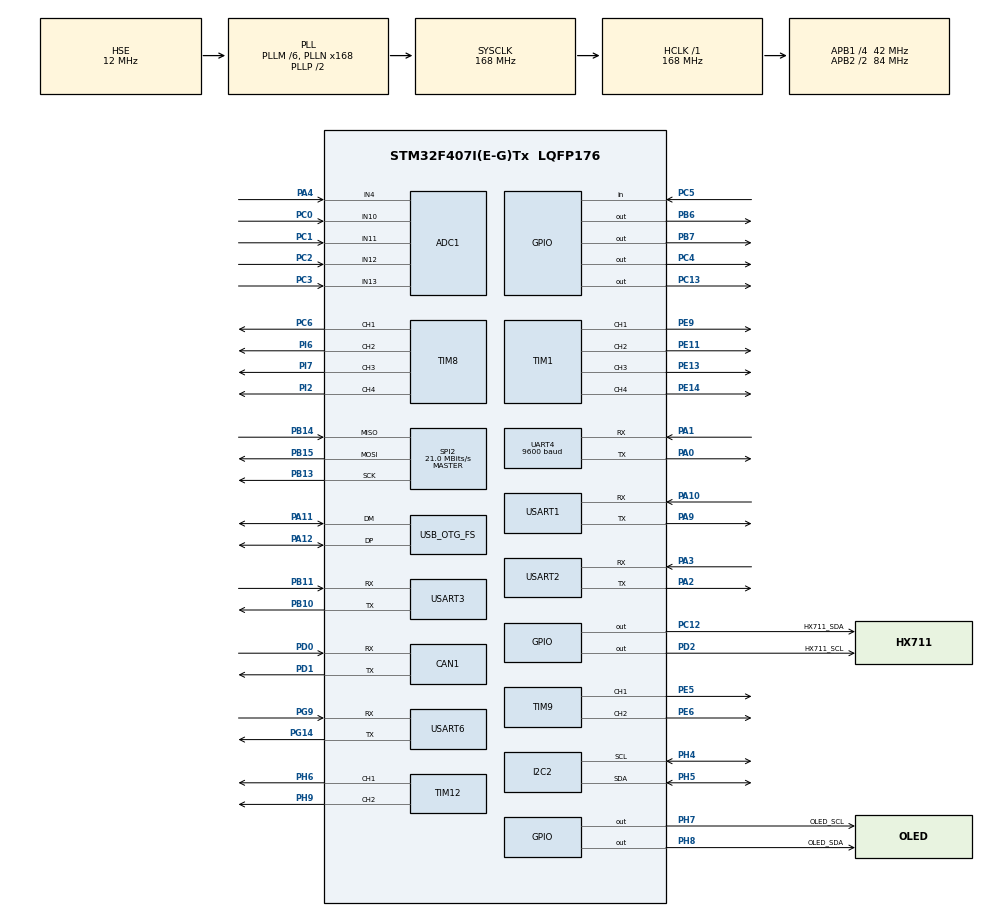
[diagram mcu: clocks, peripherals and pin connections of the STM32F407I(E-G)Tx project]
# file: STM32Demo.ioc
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ADC1.Channel-0\#ChannelRegularConversion=ADC_CHANNEL_4
ADC1.Channel-1\#ChannelRegularConversion=ADC_CHANNEL_10
ADC1.Channel-2\#ChannelRegularConversion=ADC_CHANNEL_11
ADC1.Channel-3\#ChannelRegularConversion=ADC_CHANNEL_12
ADC1.Channel-4\#ChannelRegularConversion=ADC_CHANNEL_13
ADC1.DiscontinuousConvMode=ENABLE
ADC1.NbrOfConversion=5
ADC1.NbrOfConversionFlag=1
ADC1.Rank-0\#ChannelRegularConversion=1
ADC1.Rank-1\#ChannelRegularConversion=2
ADC1.Rank-2\#ChannelRegularConversion=3
ADC1.Rank-3\#ChannelRegularConversion=4
ADC1.Rank-4\#ChannelRegularConversion=5
ADC1.SamplingTime-0\#ChannelRegularConversion=ADC_SAMPLETIME_3CYCLES
ADC1.SamplingTime-1\#ChannelRegularConversion=ADC_SAMPLETIME_3CYCLES
ADC1.SamplingTime-2\#ChannelRegularConversion=ADC_SAMPLETIME_3CYCLES
ADC1.SamplingTime-3\#ChannelRegularConversion=ADC_SAMPLETIME_3CYCLES
ADC1.SamplingTime-4\#ChannelRegularConversion=ADC_SAMPLETIME_3CYCLES
ADC1.ScanConvMode=ENABLE
ADC1.master=1
CAN1.BS1=CAN_BS1_1TQ
CAN1.BS2=CAN_BS2_1TQ
CAN1.CalculateTimeQuantum=380.95238095238096
Dma.Request0=USART1_TX
Dma.Request1=USART3_TX
Dma.Request2=USART2_TX
Dma.USART1_TX.0.Direction=DMA_MEMORY_TO_PERIPH
Dma.USART1_TX.0.FIFOMode=DMA_FIFOMODE_DISABLE
Dma.USART1_TX.0.Instance=DMA2_Stream7
Dma.USART1_TX.0.MemDataAlignment=DMA_MDATAALIGN_BYTE
Dma.USART1_TX.0.MemInc=DMA_MINC_ENABLE
Dma.USART1_TX.0.Mode=DMA_NORMAL
Dma.USART1_TX.0.PeriphDataAlignment=DMA_PDATAALIGN_BYTE
Dma.USART1_TX.0.PeriphInc=DMA_PINC_DISABLE
Dma.USART1_TX.0.Priority=DMA_PRIORITY_LOW
Dma.USART2_TX.2.Direction=DMA_MEMORY_TO_PERIPH
Dma.USART2_TX.2.FIFOMode=DMA_FIFOMODE_DISABLE
Dma.USART2_TX.2.Instance=DMA1_Stream6
Dma.USART2_TX.2.MemDataAlignment=DMA_MDATAALIGN_BYTE
Dma.USART2_TX.2.MemInc=DMA_MINC_ENABLE
Dma.USART2_TX.2.Mode=DMA_NORMAL
Dma.USART2_TX.2.PeriphDataAlignment=DMA_PDATAALIGN_BYTE
Dma.USART2_TX.2.PeriphInc=DMA_PINC_DISABLE
Dma.USART2_TX.2.Priority=DMA_PRIORITY_LOW
Dma.USART3_TX.1.Direction=DMA_MEMORY_TO_PERIPH
Dma.USART3_TX.1.FIFOMode=DMA_FIFOMODE_DISABLE
Dma.USART3_TX.1.Instance=DMA1_Stream3
Dma.USART3_TX.1.MemDataAlignment=DMA_MDATAALIGN_BYTE
Dma.USART3_TX.1.MemInc=DMA_MINC_ENABLE
Dma.USART3_TX.1.Mode=DMA_NORMAL
Dma.USART3_TX.1.PeriphDataAlignment=DMA_PDATAALIGN_BYTE
Dma.USART3_TX.1.PeriphInc=DMA_PINC_DISABLE
Dma.USART3_TX.1.Priority=DMA_PRIORITY_LOW
FREERTOS.Tasks01=Task01,24,128,StartDefaultTask,Default,NULL,Dynamic,NULL,NULL;Task02,24,128,StartTask02,Default,NULL,Dynamic,NULL,NULL;Task03,24,128,StartTask03,Default,NULL,Dynamic,NULL,NULL;Task04,24,128,StartTask04,Default,NULL,Dynamic,NULL,NULL;Task05,24,128,StartTask05,Default,NULL,Dynamic,NULL,NULL;Task06,24,128,StartTask06,Default,NULL,Dynamic,NULL,NULL
FREERTOS.configENABLE_FPU=1
Mcu.Family=STM32F4
Mcu.Name=STM32F407I(E-G)Tx
Mcu.Package=LQFP176
NVIC.DMA1_Stream3_IRQn=true\:5\:0\:false\:false\:true\:true\:false\:true
NVIC.DMA1_Stream6_IRQn=true\:5\:0\:false\:false\:true\:true\:false\:true
NVIC.DMA2_Stream7_IRQn=true\:5\:0\:false\:false\:true\:true\:false\:true
NVIC.OTG_FS_IRQn=true\:5\:0\:false\:false\:true\:false\:false\:true
NVIC.PriorityGroup=NVIC_PRIORITYGROUP_4
NVIC.TIM7_IRQn=true\:0\:0\:false\:false\:true\:false\:false\:true
NVIC.TimeBase=TIM7_IRQn
NVIC.TimeBaseIP=TIM7
NVIC.UART4_IRQn=true\:5\:0\:false\:false\:true\:false\:true\:true
NVIC.USART1_IRQn=true\:5\:0\:false\:false\:true\:false\:true\:true
NVIC.USART2_IRQn=true\:5\:0\:false\:false\:true\:false\:true\:true
NVIC.USART3_IRQn=true\:5\:0\:false\:false\:true\:false\:true\:true
NVIC.USART6_IRQn=true\:5\:0\:false\:false\:true\:false\:true\:true
PA0-WKUP.Mode=Asynchronous
PA0-WKUP.Signal=UART4_TX
PA1.Mode=Asynchronous
PA1.Signal=UART4_RX
PA10.Mode=Asynchronous
PA10.Signal=USART1_RX
PA11.Mode=Device_Only
PA11.Signal=USB_OTG_FS_DM
PA12.Mode=Device_Only
PA12.Signal=USB_OTG_FS_DP
PA13.Mode=Serial_Wire
PA13.Signal=SYS_JTMS-SWDIO
PA14.Mode=Serial_Wire
PA14.Signal=SYS_JTCK-SWCLK
PA2.Mode=Asynchronous
PA2.Signal=USART2_TX
PA3.Mode=Asynchronous
PA3.Signal=USART2_RX
PA4.Signal=ADCx_IN4
PA9.Mode=Asynchronous
PA9.Signal=USART1_TX
PB10.Mode=Asynchronous
PB10.Signal=USART3_TX
PB11.Mode=Asynchronous
PB11.Signal=USART3_RX
PB13.Mode=Full_Duplex_Master
PB13.Signal=SPI2_SCK
PB14.Mode=Full_Duplex_Master
PB14.Signal=SPI2_MISO
PB15.Mode=Full_Duplex_Master
PB15.Signal=SPI2_MOSI
PB6.GPIO_ModeDefaultOutputPP=GPIO_MODE_OUTPUT_OD
PB6.GPIO_PuPd=GPIO_PULLUP
PB6.GPIO_Speed=GPIO_SPEED_FREQ_VERY_HIGH
PB6.Signal=GPIO_Output
PB7.GPIO_ModeDefaultOutputPP=GPIO_MODE_OUTPUT_OD
PB7.GPIO_PuPd=GPIO_PULLUP
PB7.GPIO_Speed=GPIO_SPEED_FREQ_VERY_HIGH
PB7.Signal=GPIO_Output
PC0.Signal=ADCx_IN10
PC1.Signal=ADCx_IN11
PC10.Signal=SDIO_D2
PC11.Signal=SDIO_D3
PC12.GPIO_Label=HX711_SDA
PC12.GPIO_ModeDefaultOutputPP=GPIO_MODE_OUTPUT_OD
PC12.GPIO_PuPd=GPIO_PULLUP
PC12.GPIO_Speed=GPIO_SPEED_FREQ_VERY_HIGH
PC12.PinState=GPIO_PIN_SET
PC12.Signal=GPIO_Output
PC13-ANTI_TAMP.GPIO_Speed=GPIO_SPEED_FREQ_LOW
PC13-ANTI_TAMP.Signal=GPIO_Output
PC14-OSC32_IN.Mode=LSE-External-Oscillator
PC14-OSC32_IN.Signal=RCC_OSC32_IN
PC15-OSC32_OUT.Mode=LSE-External-Oscillator
PC15-OSC32_OUT.Signal=RCC_OSC32_OUT
PC2.Signal=ADCx_IN12
PC3.Signal=ADCx_IN13
PC4.GPIO_ModeDefaultOutputPP=GPIO_MODE_OUTPUT_OD
PC4.GPIO_PuPd=GPIO_PULLUP
PC4.GPIO_Speed=GPIO_SPEED_FREQ_VERY_HIGH
PC4.PinState=GPIO_PIN_SET
PC4.Signal=GPIO_Output
PC5.Signal=GPIO_Input
PC6.GPIO_Speed=GPIO_SPEED_FREQ_VERY_HIGH
PC6.Signal=S_TIM8_CH1
PC8.Signal=SDIO_D0
PC9.Signal=SDIO_D1
PD0.Mode=Master
PD0.Signal=CAN1_RX
PD1.Mode=Master
PD1.Signal=CAN1_TX
PD2.GPIO_Label=HX711_SCL
PD2.GPIO_ModeDefaultOutputPP=GPIO_MODE_OUTPUT_PP
PD2.GPIO_PuPd=GPIO_PULLUP
PD2.GPIO_Speed=GPIO_SPEED_FREQ_VERY_HIGH
PD2.PinState=GPIO_PIN_SET
PD2.Signal=GPIO_Output
PE11.GPIO_Speed=GPIO_SPEED_FREQ_VERY_HIGH
PE11.Signal=S_TIM1_CH2
PE13.GPIO_Speed=GPIO_SPEED_FREQ_VERY_HIGH
PE13.Signal=S_TIM1_CH3
PE14.GPIO_Speed=GPIO_SPEED_FREQ_VERY_HIGH
PE14.Signal=S_TIM1_CH4
PE5.GPIO_Speed=GPIO_SPEED_FREQ_VERY_HIGH
PE5.Signal=S_TIM9_CH1
PE6.GPIO_Speed=GPIO_SPEED_FREQ_VERY_HIGH
PE6.Signal=S_TIM9_CH2
PE9.GPIO_Speed=GPIO_SPEED_FREQ_VERY_HIGH
PE9.Signal=S_TIM1_CH1
PG14.Mode=Asynchronous
PG14.Signal=USART6_TX
PG9.Mode=Asynchronous
PG9.Signal=USART6_RX
PH0-OSC_IN.Mode=HSE-External-Oscillator
PH0-OSC_IN.Signal=RCC_OSC_IN
PH1-OSC_OUT.Mode=HSE-External-Oscillator
PH1-OSC_OUT.Signal=RCC_OSC_OUT
PH4.Mode=I2C
PH4.Signal=I2C2_SCL
PH5.Mode=I2C
PH5.Signal=I2C2_SDA
PH6.GPIO_Speed=GPIO_SPEED_FREQ_VERY_HIGH
PH6.Signal=S_TIM12_CH1
PH7.GPIO_Label=OLED_SCL
PH7.GPIO_ModeDefaultOutputPP=GPIO_MODE_OUTPUT_OD
PH7.GPIO_PuPd=GPIO_PULLUP
PH7.GPIO_Speed=GPIO_SPEED_FREQ_VERY_HIGH
PH7.Signal=GPIO_Output
PH8.GPIO_Label=OLED_SDA
PH8.GPIO_ModeDefaultOutputPP=GPIO_MODE_OUTPUT_OD
PH8.GPIO_PuPd=GPIO_PULLUP
PH8.GPIO_Speed=GPIO_SPEED_FREQ_VERY_HIGH
PH8.Signal=GPIO_Output
PH9.GPIO_Speed=GPIO_SPEED_FREQ_VERY_HIGH
PH9.Signal=S_TIM12_CH2
PI2.GPIO_Speed=GPIO_SPEED_FREQ_VERY_HIGH
PI2.Signal=S_TIM8_CH4
PI6.GPIO_Speed=GPIO_SPEED_FREQ_VERY_HIGH
PI6.Signal=S_TIM8_CH2
PI7.GPIO_Speed=GPIO_SPEED_FREQ_VERY_HIGH
PI7.Signal=S_TIM8_CH3
ProjectManager.HeapSize=0x200
ProjectManager.StackSize=0x400
ProjectManager.TargetToolchain=MDK-ARM V5.27
RCC.48MHZClocksFreq_Value=48000000
RCC.AHBFreq_Value=168000000
RCC.APB1CLKDivider=RCC_HCLK_DIV4
RCC.APB1Freq_Value=42000000
RCC.APB1TimFreq_Value=84000000
RCC.APB2CLKDivider=RCC_HCLK_DIV2
RCC.APB2Freq_Value=84000000
RCC.APB2TimFreq_Value=168000000
RCC.CortexFreq_Value=168000000
RCC.HCLKFreq_Value=168000000
RCC.HSE_VALUE=12000000
RCC.HSI_VALUE=16000000
RCC.PLLM=6
RCC.PLLN=168
RCC.PLLQ=7
RCC.SYSCLKFreq_VALUE=168000000
RCC.SYSCLKSource=RCC_SYSCLKSOURCE_PLLCLK
RCC.VCOOutputFreq_Value=336000000
SH.ADCx_IN10.0=ADC1_IN10,IN10
SH.ADCx_IN11.0=ADC1_IN11,IN11
SH.ADCx_IN12.0=ADC1_IN12,IN12
SH.ADCx_IN13.0=ADC1_IN13,IN13
SH.ADCx_IN4.0=ADC1_IN4,IN4
SH.S_TIM12_CH1.0=TIM12_CH1,PWM Generation1 CH1
SH.S_TIM12_CH2.0=TIM12_CH2,PWM Generation2 CH2
SH.S_TIM1_CH1.0=TIM1_CH1,PWM Generation1 CH1
SH.S_TIM1_CH2.0=TIM1_CH2,PWM Generation2 CH2
SH.S_TIM1_CH3.0=TIM1_CH3,PWM Generation3 CH3
SH.S_TIM1_CH4.0=TIM1_CH4,PWM Generation4 CH4
SH.S_TIM8_CH1.0=TIM8_CH1,PWM Generation1 CH1
SH.S_TIM8_CH2.0=TIM8_CH2,PWM Generation2 CH2
SH.S_TIM8_CH3.0=TIM8_CH3,PWM Generation3 CH3
SH.S_TIM8_CH4.0=TIM8_CH4,PWM Generation4 CH4
SH.S_TIM9_CH1.0=TIM9_CH1,PWM Generation1 CH1
SH.S_TIM9_CH2.0=TIM9_CH2,PWM Generation2 CH2
SPI2.BaudRatePrescaler=SPI_BAUDRATEPRESCALER_2
SPI2.CalculateBaudRate=21.0 MBits/s
SPI2.Direction=SPI_DIRECTION_2LINES
SPI2.Mode=SPI_MODE_MASTER
SPI2.VirtualType=VM_MASTER
TIM1.Channel-PWM\ Generation1\ CH1=TIM_CHANNEL_1
TIM1.Channel-PWM\ Generation2\ CH2=TIM_CHANNEL_2
TIM1.Channel-PWM\ Generation3\ CH3=TIM_CHANNEL_3
TIM1.Channel-PWM\ Generation4\ CH4=TIM_CHANNEL_4
TIM12.Channel-PWM\ Generation1\ CH1=TIM_CHANNEL_1
TIM12.Channel-PWM\ Generation2\ CH2=TIM_CHANNEL_2
TIM8.Channel-PWM\ Generation1\ CH1=TIM_CHANNEL_1
TIM8.Channel-PWM\ Generation2\ CH2=TIM_CHANNEL_2
TIM8.Channel-PWM\ Generation3\ CH3=TIM_CHANNEL_3
TIM8.Channel-PWM\ Generation4\ CH4=TIM_CHANNEL_4
TIM9.Channel-PWM\ Generation1\ CH1=TIM_CHANNEL_1
TIM9.Channel-PWM\ Generation2\ CH2=TIM_CHANNEL_2
UART4.BaudRate=9600
UART4.VirtualMode=Asynchronous
USART1.VirtualMode=VM_ASYNC
USART2.VirtualMode=VM_ASYNC
USART3.VirtualMode=VM_ASYNC
USART6.VirtualMode=VM_ASYNC
USB_DEVICE.CLASS_NAME_FS=MSC
USB_DEVICE.VirtualMode-MSC_FS=Msc
USB_DEVICE.VirtualModeFS=Msc_FS
USB_OTG_FS.VirtualMode=Device_Only
VP_FATFS_VS_Generic.Mode=User_defined
VP_FREERTOS_VS_CMSIS_V2.Mode=CMSIS_V2
VP_SYS_VS_tim7.Mode=TIM7
VP_TIM1_VS_ClockSourceINT.Mode=Internal
VP_TIM8_VS_ClockSourceINT.Mode=Internal
VP_TIM9_VS_ClockSourceINT.Mode=Internal
VP_USB_DEVICE_VS_USB_DEVICE_MSC_FS.Mode=MSC_FS
board=custom

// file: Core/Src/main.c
/* USER CODE BEGIN Header */
/**
  ******************************************************************************
  * @file           : main.c
  * @brief          : Main program body
  ******************************************************************************
  * @attention
  *
  * <h2><center>&copy; Copyright (c) 2021 STMicroelectronics.
  * All rights reserved.</center></h2>
  *
  * This software component is licensed by ST under BSD 3-Clause license,
  * the "License"; You may not use this file except in compliance with the
  * License. You may obtain a copy of the License at:
  *                        opensource.org/licenses/BSD-3-Clause
  *
  ******************************************************************************
  */
/* USER CODE END Header */
#include "main.h"
#include "cmsis_os.h"
#include "adc.h"
#include "can.h"
#include "dma.h"
#include "fatfs.h"
#include "i2c.h"
#include "spi.h"
#include "tim.h"
#include "usart.h"
#include "usb_device.h"
#include "gpio.h"

void SystemClock_Config(void);
void MX_FREERTOS_Init(void);

int main(void)
{

  /* MCU Configuration--------------------------------------------------------*/

  /* Reset of all peripherals, Initializes the Flash interface and the Systick. */  HAL_Init();

  /* Configure the system clock */
  SystemClock_Config();

  /* Initialize all configured peripherals */
  MX_GPIO_Init();
  MX_DMA_Init();
  MX_ADC1_Init();
  MX_CAN1_Init();
  MX_I2C2_Init();
  MX_SPI2_Init();
  MX_TIM1_Init();
  MX_TIM8_Init();
  MX_TIM9_Init();
  MX_TIM12_Init();
  MX_UART4_Init();
  MX_USART1_UART_Init();
  MX_USART2_UART_Init();
  MX_USART3_UART_Init();
  MX_USART6_UART_Init();
  MX_FATFS_Init();

  /* Init scheduler */
  osKernelInitialize();  /* Call init function for freertos objects (in freertos.c) */
  MX_FREERTOS_Init();
  /* Start scheduler */
  osKernelStart();

  /* We should never get here as control is now taken by the scheduler */
  /* Infinite loop */
  while (1)
  {

  }
}

void SystemClock_Config(void)
{
  RCC_OscInitTypeDef RCC_OscInitStruct = {0};
  RCC_ClkInitTypeDef RCC_ClkInitStruct = {0};

  /** Configure the main internal regulator output voltage
  */
  __HAL_RCC_PWR_CLK_ENABLE();
  __HAL_PWR_VOLTAGESCALING_CONFIG(PWR_REGULATOR_VOLTAGE_SCALE1);
  /** Initializes the RCC Oscillators according to the specified parameters
  * in the RCC_OscInitTypeDef structure.
  */
  RCC_OscInitStruct.OscillatorType = RCC_OSCILLATORTYPE_HSE;
  RCC_OscInitStruct.HSEState = RCC_HSE_ON;
  RCC_OscInitStruct.PLL.PLLState = RCC_PLL_ON;
  RCC_OscInitStruct.PLL.PLLSource = RCC_PLLSOURCE_HSE;
  RCC_OscInitStruct.PLL.PLLM = 6;
  RCC_OscInitStruct.PLL.PLLN = 168;
  RCC_OscInitStruct.PLL.PLLP = RCC_PLLP_DIV2;
  RCC_OscInitStruct.PLL.PLLQ = 7;
  if (HAL_RCC_OscConfig(&RCC_OscInitStruct) != HAL_OK)
  {
    Error_Handler();
  }
  /** Initializes the CPU, AHB and APB buses clocks
  */
  RCC_ClkInitStruct.ClockType = RCC_CLOCKTYPE_HCLK|RCC_CLOCKTYPE_SYSCLK
                              |RCC_CLOCKTYPE_PCLK1|RCC_CLOCKTYPE_PCLK2;
  RCC_ClkInitStruct.SYSCLKSource = RCC_SYSCLKSOURCE_PLLCLK;
  RCC_ClkInitStruct.AHBCLKDivider = RCC_SYSCLK_DIV1;
  RCC_ClkInitStruct.APB1CLKDivider = RCC_HCLK_DIV4;
  RCC_ClkInitStruct.APB2CLKDivider = RCC_HCLK_DIV2;

  if (HAL_RCC_ClockConfig(&RCC_ClkInitStruct, FLASH_LATENCY_5) != HAL_OK)
  {
    Error_Handler();
  }
}

void HAL_TIM_PeriodElapsedCallback(TIM_HandleTypeDef *htim)
{
  if (htim->Instance == TIM7) {
    HAL_IncTick();
  }
}

void Error_Handler(void)
{
}

/************************ (C) COPYRIGHT STMicroelectronics *****END OF FILE****/

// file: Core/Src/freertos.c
/* USER CODE BEGIN Header */
/**
  ******************************************************************************
  * File Name          : freertos.c
  * Description        : Code for freertos applications
  ******************************************************************************
  * @attention
  *
  * <h2><center>&copy; Copyright (c) 2021 STMicroelectronics.
  * All rights reserved.</center></h2>
  *
  * This software component is licensed by ST under Ultimate Liberty license
  * SLA0044, the "License"; You may not use this file except in compliance with
  * the License. You may obtain a copy of the License at:
  *                             www.st.com/SLA0044
  *
  ******************************************************************************
  */
/* USER CODE END Header */

#include "FreeRTOS.h"
#include "task.h"
#include "main.h"
#include "cmsis_os.h"

/* USER CODE BEGIN Includes */
#include "Task01Main.h"
#include "Task02Main.h"
#include "Task03Main.h"
#include "Task04Main.h"
#include "Task05Main.h"
#include "Task06Main.h"
/* USER CODE END Includes */

/* Definitions for Task01 */
osThreadId_t Task01Handle;
const osThreadAttr_t Task01_attributes = {
  .name = "Task01",
  .priority = (osPriority_t) osPriorityNormal,
  .stack_size = 128 * 4
};
/* Definitions for Task02 */
osThreadId_t Task02Handle;
const osThreadAttr_t Task02_attributes = {
  .name = "Task02",
  .priority = (osPriority_t) osPriorityNormal,
  .stack_size = 128 * 4
};
/* Definitions for Task03 */
osThreadId_t Task03Handle;
const osThreadAttr_t Task03_attributes = {
  .name = "Task03",
  .priority = (osPriority_t) osPriorityNormal,
  .stack_size = 128 * 4
};
/* Definitions for Task04 */
osThreadId_t Task04Handle;
const osThreadAttr_t Task04_attributes = {
  .name = "Task04",
  .priority = (osPriority_t) osPriorityNormal,
  .stack_size = 128 * 4
};
/* Definitions for Task05 */
osThreadId_t Task05Handle;
const osThreadAttr_t Task05_attributes = {
  .name = "Task05",
  .priority = (osPriority_t) osPriorityNormal,
  .stack_size = 128 * 4
};
/* Definitions for Task06 */
osThreadId_t Task06Handle;
const osThreadAttr_t Task06_attributes = {
  .name = "Task06",
  .priority = (osPriority_t) osPriorityNormal,
  .stack_size = 128 * 4
};

void StartDefaultTask(void *argument);
void StartTask02(void *argument);
void StartTask03(void *argument);
void StartTask04(void *argument);
void StartTask05(void *argument);
void StartTask06(void *argument);

extern void MX_USB_DEVICE_Init(void);
void MX_FREERTOS_Init(void); /* (MISRA C 2004 rule 8.1) */

void MX_FREERTOS_Init(void) {

  /* Create the thread(s) */
  /* creation of Task01 */
  Task01Handle = osThreadNew(StartDefaultTask, NULL, &Task01_attributes);

  /* creation of Task02 */
  Task02Handle = osThreadNew(StartTask02, NULL, &Task02_attributes);

  /* creation of Task03 */
  Task03Handle = osThreadNew(StartTask03, NULL, &Task03_attributes);

  /* creation of Task04 */
  Task04Handle = osThreadNew(StartTask04, NULL, &Task04_attributes);

  /* creation of Task05 */
  Task05Handle = osThreadNew(StartTask05, NULL, &Task05_attributes);

  /* creation of Task06 */
  Task06Handle = osThreadNew(StartTask06, NULL, &Task06_attributes);

}

void StartDefaultTask(void *argument)
{
  /* init code for USB_DEVICE */
  MX_USB_DEVICE_Init();
  /* USER CODE BEGIN StartDefaultTask */
  /* Infinite loop */
  for(;;)
  {
		Task01Main();
    osDelay(1);
  }
  /* USER CODE END StartDefaultTask */
}

void StartTask02(void *argument)
{
  /* USER CODE BEGIN StartTask02 */
  /* Infinite loop */
  for(;;)
  {
		Task02Main();
    osDelay(1);
  }
  /* USER CODE END StartTask02 */
}

void StartTask03(void *argument)
{
  /* USER CODE BEGIN StartTask03 */
  /* Infinite loop */
  for(;;)
  {
		Task03Main();
    osDelay(1);
  }
  /* USER CODE END StartTask03 */
}

void StartTask04(void *argument)
{
  /* USER CODE BEGIN StartTask04 */
  /* Infinite loop */
  for(;;)
  {
		Task04Main();
    osDelay(1);
  }
  /* USER CODE END StartTask04 */
}

void StartTask05(void *argument)
{
  /* USER CODE BEGIN StartTask05 */
  /* Infinite loop */
  for(;;)
  {
		Task05Main();
    osDelay(1);
  }
  /* USER CODE END StartTask05 */
}

void StartTask06(void *argument)
{
  /* USER CODE BEGIN StartTask06 */
  /* Infinite loop */
  for(;;)
  {
		Task06Main();
    osDelay(1);
  }
  /* USER CODE END StartTask06 */
}

/************************ (C) COPYRIGHT STMicroelectronics *****END OF FILE****/
